# V8M_Generic register map
Vendor: ARM Ltd.; Series: M; File version: 2020-08-22T15:13:24.354567-05:00
CPU: CM4 r0p0, little endian, vendor SysTick, 8 interrupt priority bits
Registers are 32-bit, read-write, no defined reset value unless marked. A register's access mark holds for its fields unless they carry their own. Offsets are from the block's base; [hi:lo] are bit positions; 'fields as' and 'values as' point back to an identical list.

## FPE — Floating Point Control Registers
Base 0xE000EF34
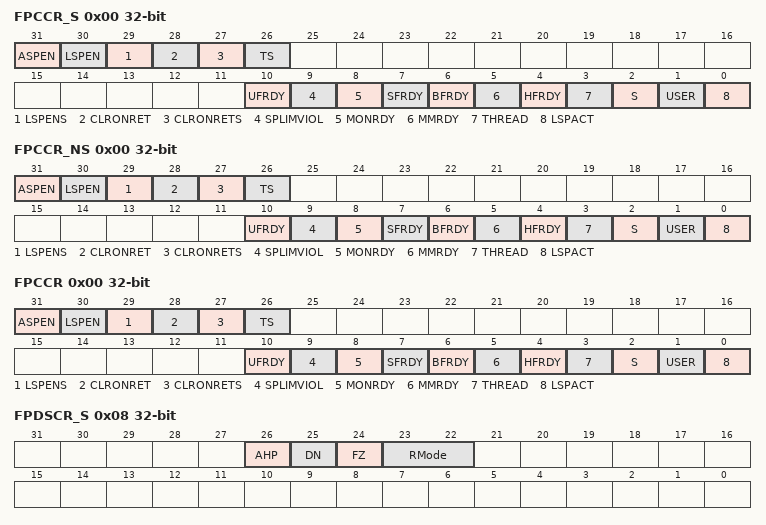
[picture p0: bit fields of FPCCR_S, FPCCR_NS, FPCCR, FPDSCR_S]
0x00 FPCCR_S — Holds control data for the Floating Point Unit
  [31] ASPEN — When this bit is set to 1, execution of a floating-point instruction sets the CONTROL.FPCA bit to 1
    0=Executing_an_FP_instruction_has_no_effect_on_CONTROL; 1=Executing_an_FP_instruction_sets_CONTROL
  [30] LSPEN — Enables lazy context save of FP state
    0=Disable_automatic_lazy_context_save; 1=Enable_automatic_lazy_context_save
  [29] LSPENS — This bit controls whether the LSPEN bit is writeable from the Non-secure state. This behaves as RAZ/WI when accessed from the Non-secure state
    0=LSPEN_is_readable_and_writeable_from_both_Security_states; 1=LSPEN_is_readable_from_both_Security_states_but_writes_to_LSPEN_are_ignored_from_the_Non_secure_state
  [28] CLRONRET — Clear floating point caller saved registers on exception return
    0=Disabled; 1=Enabled
  [27] CLRONRETS — CLRONRET Secure only
    0=The_CLRONRET_field_is_accessibly_from_both_Security_states; 1=The_Non_secure_view_of_the_CLRONRET_field_is_read_only
  [26] TS — Treat FP registers as Secure enable
    0=Disabled; 1=Enabled
  [10] UFRDY — Indicates whether the software executing when the processor allocated the FP stack frame was able to set the UsageFault exception to pending
    0=Not_able_to_set_the_UsageFault_exception_to_pending; 1=Able_to_set_the_UsageFault_exception_to_pending
  [9] SPLIMVIOL — This bit is banked between the Security states and indicates whether the FP context violates the stack pointer limit that was active when lazy state preservation was activated. SPLIMVIOL modifies the lazy FP state preservation behaviour
    0=The_existing_behavior_is_retained; 1=The_memory_accesses_associated_with_the_floating_point_state_preservation_are_not_performed
  [8] MONRDY — Indicates whether the software executing when the processor allocated the FP stack frame was able to set the DebugMonitor exception to pending
    0=Not_able_to_set_the_DebugMonitor_exception_to_pending; 1=Able_to_set_the_DebugMonitor_exception_to_pending
  [7] SFRDY — Indicates whether the software executing when the processor allocated the FP stack frame was able to set the SecureFault exception to pending. This bit is only present in the Secure version of the register, and behaves as RAZ/WI when accessed from the Non-secure state
  [6] BFRDY — Indicates whether the software executing when the processor allocated the FP stack frame was able to set the BusFault exception to pending
    0=Not_able_to_set_the_BusFault_exception_to_pending; 1=Able_to_set_the_BusFault_exception_to_pending
  [5] MMRDY — Indicates whether the software executing when the processor allocated the FP stack frame was able to set the MemManage exception to pending
    0=Not_able_to_set_the_MemManage_exception_to_pending; 1=Able_to_set_the_MemManage_exception_to_pending
  [4] HFRDY — Indicates whether the software executing when the processor allocated the FP stack frame was able to set the HardFault exception to pending
    0=Not_able_to_set_the_HardFault_exception_to_pending; 1=Able_to_set_the_HardFault_exception_to_pending
  [3] THREAD — Indicates the processor mode when it allocated the FP stack frame
    0=Handler_mode; 1=Thread_mode
  [2] S — Security status of the FP context. This bit is only present in the Secure version of the register, and behaves as RAZ/WI when accessed from the Non-secure state. This bit is updated whenever lazy state preservation is activated, or when a floating point instruction is executed
    0=Indicates_the_FP_context_belongs_to_the_non_secure_state; 0=Indicates_the_FP_context_belongs_to_the_secure_state
  [1] USER — Indicates the privilege level of the software executing when the processor allocated the FP stack frame
    0=Privileged; 1=Unprivileged
  [0] LSPACT — Indicates whether lazy preservation of the FP state is active
    0=Lazy_state_preservation_is_not_active; 1=Lazy_state_preservation_is_active
0x00 FPCCR_NS — Holds control data for the Floating Point Unit
  fields as FPCCR_S
0x00 FPCCR — Holds control data for the Floating Point Unit
  fields as FPCCR_S
0x04 FPCAR_S — Holds the location of the unpopulated floating-point register space allocated on an exception stack frame
  [31:3] ADDRESS
0x04 FPCAR_NS — Holds the location of the unpopulated floating-point register space allocated on an exception stack frame
  [31:3] ADDRESS
0x04 FPCAR — Holds the location of the unpopulated floating-point register space allocated on an exception stack frame
  [31:3] ADDRESS
0x08 FPDSCR_S — Holds the default values for the floating-point status control data that the PE assigns to the FPSCR when it creates a new floating-point context
  [26] AHP — Alternative half-precision
  [25] DN — Default NaN
  [24] FZ — Flush-to-zero
  [23:22] RMode — Rounding mode
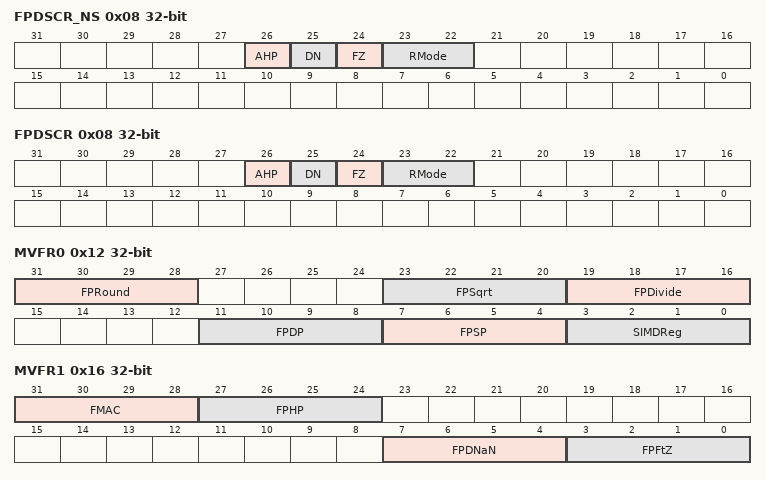
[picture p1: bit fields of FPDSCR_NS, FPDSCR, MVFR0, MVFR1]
0x08 FPDSCR_NS — Holds the default values for the floating-point status control data that the PE assigns to the FPSCR when it creates a new floating-point context
  fields as FPDSCR_S
0x08 FPDSCR — Holds the default values for the floating-point status control data that the PE assigns to the FPSCR when it creates a new floating-point context
  fields as FPDSCR_S
0x12 MVFR0 ro — Describes the features provided by the Floating-point Extension
  [31:28] FPRound — Floating-point rounding modes
    1=All_rounding_modes_supported
  [23:20] FPSqrt — Floating-point square root
    1=Supported
  [19:16] FPDivide — Floating-point divide
    1=Supported
  [11:8] FPDP — Floating-point double-precision
    0=Not_supported; 2=Supported
  [7:4] FPSP — Floating-point single-precision
    2=Supported
  [3:0] SIMDReg — SIMD registers
    1=_16_64_bit_registers
0x16 MVFR1 ro — Describes the features provided by the Floating-point Extension
  [31:28] FMAC — Fused multiply accumulate
    1=Implemented
  [27:24] FPHP — Floating-point half-precision
    1=Half_precision_to_single_precision_implemented; 2=Half_precision_to_single_and_double_precision_implemented
  [7:4] FPDNaN — Floating-point default NaN
    1=Propagation_of_NaN_values_supported
  [3:0] FPFtZ — Floating-point flush-to-zero
    1=Full_denormalized_numbers_arithmetic_supported
0x20 MVFR2 ro — Describes the features provided by the Floating-point Extension
  [7:4] FPMisc — Floating-point miscellaneous
    4=Selection_directed_conversion_to_integer_VMINNM_and_VMAXNM_supported
